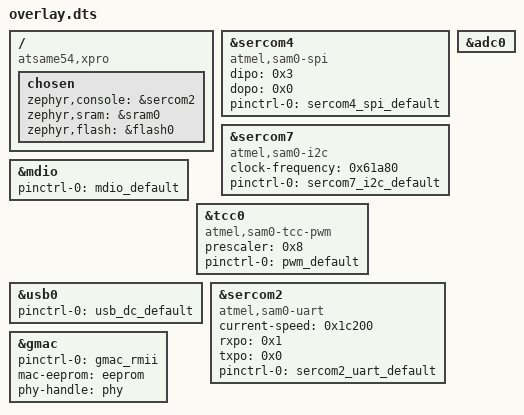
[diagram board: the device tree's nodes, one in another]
/ {
	compatible = "atsame54,xpro", "atmel,same54p20a", "atmel,same54";
	chosen {
		zephyr,console = &sercom2;
		zephyr,sram = &sram0;
		zephyr,flash = &flash0;
	};
};
&sercom4{
	compatible = "atmel,sam0-spi";
	status = "okay";
	dipo = < 0x3 >;
	dopo = < 0x0 >;
	#address-cells = < 0x1 >;
	#size-cells = < 0x0 >;
	pinctrl-0 = < &sercom4_spi_default >;
	pinctrl-names = "default";
};
&sercom7{
	compatible = "atmel,sam0-i2c";
	status = "okay";
	clock-frequency = < 0x61a80 >;
	#address-cells = < 0x1 >;
	#size-cells = < 0x0 >;
	pinctrl-0 = < &sercom7_i2c_default >;
	pinctrl-names = "default";
};
&mdio{
	status = "okay";
	pinctrl-0 = < &mdio_default >;
	pinctrl-names = "default";
};
&adc0{
	status = "okay";
};
&tcc0{
	compatible = "atmel,sam0-tcc-pwm";
	status = "okay";
	prescaler = < 0x8 >;
	#pwm-cells = < 0x2 >;
	pinctrl-0 = < &pwm_default >;
	pinctrl-names = "default";
};
&usb0{
	status = "okay";
	pinctrl-0 = < &usb_dc_default >;
	pinctrl-names = "default";
};
&sercom2{
	compatible = "atmel,sam0-uart";
	status = "okay";
	current-speed = < 0x1c200 >;
	rxpo = < 0x1 >;
	txpo = < 0x0 >;
	#address-cells = < 0x1 >;
	#size-cells = < 0x0 >;
	pinctrl-0 = < &sercom2_uart_default >;
	pinctrl-names = "default";
};
&gmac{
	status = "okay";
	pinctrl-0 = < &gmac_rmii >;
	pinctrl-names = "default";
	mac-eeprom = < &eeprom >;
	phy-handle = < &phy >;
};
